# STM32H7B3x register map
File version: 2.2
CPU: CM7 r0p1, little endian, MPU, FPU, 4 interrupt priority bits
Registers are 32-bit, read-write, reset 0x0 unless marked. A register's access mark holds for its fields unless they carry their own. Offsets are from the block's base; [hi:lo] are bit positions; lines under a group give offsets from that group; {n}, {i} and the like mark numbered series.

## DFSDM1 — Digital filter for sigma delta modulators
Base 0x40017800
Same registers: DFSDM2 0x58006C00
{0x0+0x20*i} CH{i} (i=0..7) group — Cluster CH{i}, containing CH?CFGR1, CH?CFGR2, CH?AWSCDR, CH?WDATR, CH?DATINR, CH?DLYR
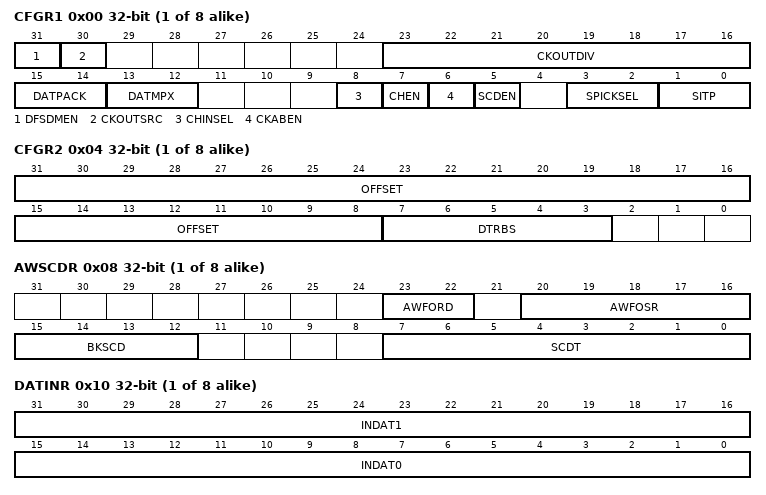
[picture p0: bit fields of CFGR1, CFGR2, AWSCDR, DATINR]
  0x00 CFGR1 — DFSDM channel 0 configuration register
    [31] DFSDMEN — Global enable for DFSDM interface If DFSDM interface is enabled, then it is started to operate according to enabled y channels and enabled x filters settings (CHEN bit in DFSDM_CHyCFGR1 and DFEN bit in DFSDM_FLTxCR1). Data cleared by setting DFSDMEN=0: all registers DFSDM_FLTxISR are set to reset state (x = 0..7) all registers DFSDM_FLTxAWSR are set to reset state (x = 0..7) Note: DFSDMEN is present only in DFSDM_CH0CFGR1 register (channel y=0)
    [30] CKOUTSRC — Output serial clock source selection This value can be modified only when DFSDMEN=0 (in DFSDM_CH0CFGR1 register). Note: CKOUTSRC is present only in DFSDM_CH0CFGR1 register (channel y=0)
    [23:16] CKOUTDIV — Output serial clock divider Â 256 (Divider = CKOUTDIV+1). CKOUTDIV also defines the threshold for a clock absence detection. This value can only be modified when DFSDMEN=0 (in DFSDM_CH0CFGR1 register). If DFSDMEN=0 (in DFSDM_CH0CFGR1 register) then CKOUT signal is set to low state (setting is performed one DFSDM clock cycle after DFSDMEN=0). Note: CKOUTDIV is present only in DFSDM_CH0CFGR1 register (channel y=0) 1- 255: Defines the division of system clock for the serial clock output for CKOUT signal in range 2Â -
    [15:14] DATPACK — Data packing mode in DFSDM_CHyDATINR register. first sample in INDAT0[15:0] (assigned to channel y) second sample INDAT1[15:0] (assigned to channel y) To empty DFSDM_CHyDATINR register, two samples must be read by the digital filter from channel y (INDAT0[15:0] part is read as first sample and then INDAT1[15:0] part is read as next sample). 2: Dual: input data in DFSDM_CHyDATINR register are stored as two samples: first sample INDAT0[15:0] (assigned to channel y) second sample INDAT1[15:0] (assigned to channel y+1) To empty DFSDM_CHyDATINR register first sample must be read by the digital filter from channel y and second sample must be read by another digital filter from channel y+1. Dual mode is available only on even channel numbers (y = 0, 2, 4, 6), for odd channel numbers (y = 1, 3, 5, 7) DFSDM_CHyDATINR is write protected. If an even channel is set to dual mode then the following odd channel must be set into standard mode (DATPACK[1:0]=0) for correct cooperation with even channel. 3: Reserved This value can be modified only when CHEN=0 (in DFSDM_CHyCFGR1 register).
    [13:12] DATMPX — Input data multiplexer for channel y 2: Data to channel y are taken from internal DFSDM_CHyDATINR register by direct CPU/DMA write. There can be written one or two 16-bit data samples according DATPACK[1:0] bit field setting. 3: Reserved This value can be modified only when CHEN=0 (in DFSDM_CHyCFGR1 register).
    [8] CHINSEL — Channel inputs selection This value can be modified only when CHEN=0 (in DFSDM_CHyCFGR1 register).
    [7] CHEN — Channel y enable If channel y is enabled, then serial data receiving is started according to the given channel setting.
    [6] CKABEN — Clock absence detector enable on channel y
    [5] SCDEN — Short-circuit detector enable on channel y
    [3:2] SPICKSEL — SPI clock select for channel y 2: clock coming from internal CKOUT - sampling point on each second CKOUT falling edge. For connection to external Î£â modulator which divides its clock input (from CKOUT) by 2 to generate its output serial communication clock (and this output clock change is active on each clock input rising edge). 3: clock coming from internal CKOUT output - sampling point on each second CKOUT rising edge. For connection to external Î£â modulator which divides its clock input (from CKOUT) by 2 to generate its output serial communication clock (and this output clock change is active on each clock input falling edge). This value can be modified only when CHEN=0 (in DFSDM_CHyCFGR1 register).
    [1:0] SITP — Serial interface type for channel y This value can only be modified when CHEN=0 (in DFSDM_CHyCFGR1 register).
  0x04 CFGR2 — DFSDM channel 0 configuration register
    [31:8] OFFSET — 24-bit calibration offset for channel y For channel y, OFFSET is applied to the results of each conversion from this channel. This value is set by software.
    [7:3] DTRBS — Data right bit-shift for channel y will be performed to have final results. Bit-shift is performed before offset correction. The data shift is rounding the result to nearest integer value. The sign of shifted result is maintained (to have valid 24-bit signed format of result data). This value can be modified only when CHEN=0 (in DFSDM_CHyCFGR1 register). 0-31: Defines the shift of the data result coming from the integrator - how many bit shifts to the right
  0x08 AWSCDR — DFSDM channel 0 analog watchdog and short-circuit detector register
    [23:22] AWFORD — Analog watchdog Sinc filter order on channel y 2: Sinc2 filter type 3: Sinc3 filter type Sincx filter type transfer function: FastSinc filter type transfer function: This bit can be modified only when CHEN=0 (in DFSDM_CHyCFGR1 register).
    [20:16] AWFOSR — Analog watchdog filter oversampling ratio (decimation rate) on channel y also the decimation ratio of the analog data rate. This bit can be modified only when CHEN=0 (in DFSDM_CHyCFGR1 register). Note: If AWFOSR = 0 then the filter has no effect (filter bypass). 0 - 31: Defines the length of the Sinc type filter in the range 1 - 32 (AWFOSR + 1). This number is
    [15:12] BKSCD — Break signal assignment for short-circuit detector on channel y BKSCD[i] = 0: Break i signal not assigned to short-circuit detector on channel y BKSCD[i] = 1: Break i signal assigned to short-circuit detector on channel y
    [7:0] SCDT — short-circuit detector threshold for channel y These bits are written by software to define the threshold counter for the short-circuit detector. If this value is reached, then a short-circuit detector event occurs on a given channel.
  0x0C WDATR ro — DFSDM channel 0 watchdog filter data register
    [15:0] WDATA — Input channel y watchdog data Data converted by the analog watchdog filter for input channel y. This data is continuously converted (no trigger) for this channel, with a limited resolution (OSR=1..32/sinc order = 1..3).
  0x10 DATINR — DFSDM channel 0 data input register
    [31:16] INDAT1 — Input data for channel y or channel y+1 Input parallel channel data to be processed by the digital filter if DATMPX[1:0]=1 or DATMPX[1:0]=2. Data can be written by CPU/DMA (if DATMPX[1:0]=2) or directly by internal ADC (if DATMPX[1:0]=1). If DATPACK[1:0]=0 (standard mode) INDAT0[15:0] is write protected (not used for input sample). If DATPACK[1:0]=1 (interleaved mode) Second channel y data sample is stored into INDAT1[15:0]. First channel y data sample is stored into INDAT0[15:0]. Both samples are read sequentially by DFSDM_FLTx filter as two channel y data samples. If DATPACK[1:0]=2 (dual mode). For even y channels: sample in INDAT1[15:0] is automatically copied into INDAT0[15:0] of channel (y+1). For odd y channels: INDAT1[15:0] is write protected. See for more details. INDAT0[15:1] is in the16-bit signed format.
    [15:0] INDAT0 — Input data for channel y Input parallel channel data to be processed by the digital filter if DATMPX[1:0]=1 or DATMPX[1:0]=2. Data can be written by CPU/DMA (if DATMPX[1:0]=2) or directly by internal ADC (if DATMPX[1:0]=1). If DATPACK[1:0]=0 (standard mode) Channel y data sample is stored into INDAT0[15:0]. If DATPACK[1:0]=1 (interleaved mode) First channel y data sample is stored into INDAT0[15:0]. Second channel y data sample is stored into INDAT1[15:0]. Both samples are read sequentially by DFSDM_FLTx filter as two channel y data samples. If DATPACK[1:0]=2 (dual mode). For even y channels: Channel y data sample is stored into INDAT0[15:0]. For odd y channels: INDAT0[15:0] is write protected. See for more details. INDAT0[15:0] is in the16-bit signed format.
  0x14 DLYR
    [5:0] PLSSKP — Pulses to skip for input data skipping function immediately after writing to this field. Reading of PLSSKP[5:0] returns current value of pulses which will be skipped. If PLSSKP[5:0]=0 then all required data samples were already skipped. Note: User can update PLSSKP[5:0] also when PLSSKP[5:0] is not zero. 0-63: Defines the number of serial input samples that will be skipped. Skipping is applied
{0x100+0x80*i} FLT{i} (i=0..7) group — Cluster FLT{i}, containing FLT?CR1, FLT?CR2, FLT?ISR, FLT?ICR, FLT?JCHGR, FLT?FCR, FLT?JDATAR, FLT?RDATAR, FLT?AWHTR, FLT?AWLTR, FLT?AWSR, FLT?AWCFR, FLT?EXMAX, FLT?EXMIN, FLT?CNVTIMR
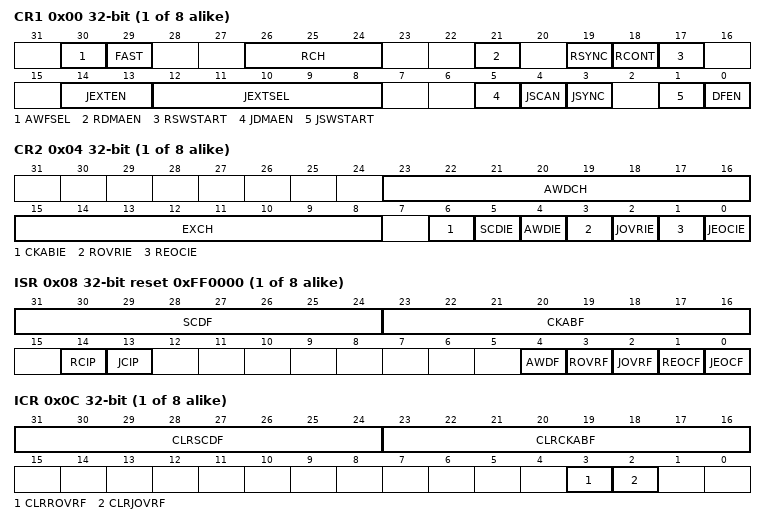
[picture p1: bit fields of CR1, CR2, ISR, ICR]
  0x00 CR1
    [30] AWFSEL — Analog watchdog fast mode select
    [29] FAST — Fast conversion mode selection for regular conversions When converting a regular conversion in continuous mode, having enabled the fast mode causes each conversion (except the first) to execute faster than in standard mode. This bit has no effect on conversions which are not continuous. This bit can be modified only when DFEN=0 (DFSDM_FLTxCR1). if FAST=0 (or first conversion in continuous mode if FAST=1): t = [FOSR * (IOSR-1 + FORD) + FORD] / fCKIN ..... for Sincx filters t = [FOSR * (IOSR-1 + 4) + 2] / fCKIN ..... for FastSinc filter if FAST=1 in continuous mode (except first conversion): t = [FOSR * IOSR] / fCKIN in case if FOSR = FOSR[9:0]+1 = 1 (filter bypassed, active only integrator): t = IOSR / fCKIN (... but CNVCNT=0) where: fCKIN is the channel input clock frequency (on given channel CKINy pin) or input data rate in case of parallel data input.
    [26:24] RCH — Regular channel selection ... 7: Channel 7 is selected as the regular channel Writing these bits when RCIP=1 takes effect when the next regular conversion begins. This is especially useful in continuous mode (when RCONT=1). It also affects regular conversions which are pending (due to ongoing injected conversion).
    [21] RDMAEN — DMA channel enabled to read data for the regular conversion This bit can be modified only when DFEN=0 (DFSDM_FLTxCR1).
    [19] RSYNC — Launch regular conversion synchronously with DFSDM_FLT0 This bit can be modified only when DFEN=0 (DFSDM_FLTxCR1).
    [18] RCONT — Continuous mode selection for regular conversions Writing '0â to this bit while a continuous regular conversion is already in progress stops the continuous mode immediately.
    [17] RSWSTART — Software start of a conversion on the regular channel This bit is always read as '0â.
    [14:13] JEXTEN — Trigger enable and trigger edge selection for injected conversions This bit can be modified only when DFEN=0 (DFSDM_FLTxCR1).
    [12:8] JEXTSEL — Trigger signal selection for launching injected conversions This bit can be modified only when DFEN=0 (DFSDM_FLTxCR1). Note: synchronous trigger has latency up to one fDFSDMCLK clock cycle (with deterministic jitter), asynchronous trigger has latency 2-3 fDFSDMCLK clock cycles (with jitter up to 1 cycle). DFSDM_FLTx 0x00 dfsdm_jtrg0 0x01 dfsdm_jtrg1 ... 0x1E dfsdm_jtrg30 0x1F dfsdm_jtrg31 Refer to . 0x0-0x1F: Trigger inputs selected by the following table (internal or external trigger).
    [5] JDMAEN — DMA channel enabled to read data for the injected channel group This bit can be modified only when DFEN=0 (DFSDM_FLTxCR1).
    [4] JSCAN — Scanning conversion mode for injected conversions This bit can be modified only when DFEN=0 (DFSDM_FLTxCR1). Writing JCHG if JSCAN=0 resets the channel selection to the lowest selected channel.
    [3] JSYNC — Launch an injected conversion synchronously with the DFSDM_FLT0 JSWSTART trigger This bit can be modified only when DFEN=0 (DFSDM_FLTxCR1).
    [1] JSWSTART — Start a conversion of the injected group of channels This bit is always read as '0â.
    [0] DFEN — DFSDM_FLTx enable Data which are cleared by setting DFEN=0: register DFSDM_FLTxISR is set to the reset state register DFSDM_FLTxAWSR is set to the reset state
  0x04 CR2
    [23:16] AWDCH — Analog watchdog channel selection These bits select the input channel to be guarded continuously by the analog watchdog. AWDCH[y] = 0: Analog watchdog is disabled on channel y AWDCH[y] = 1: Analog watchdog is enabled on channel y
    [15:8] EXCH — Extremes detector channel selection These bits select the input channels to be taken by the Extremes detector. EXCH[y] = 0: Extremes detector does not accept data from channel y EXCH[y] = 1: Extremes detector accepts data from channel y
    [6] CKABIE — Clock absence interrupt enable Please see the explanation of CKABF[7:0] in DFSDM_FLTxISR. Note: CKABIE is present only in DFSDM_FLT0CR2 register (filter x=0)
    [5] SCDIE — Short-circuit detector interrupt enable Please see the explanation of SCDF[7:0] in DFSDM_FLTxISR. Note: SCDIE is present only in DFSDM_FLT0CR2 register (filter x=0)
    [4] AWDIE — Analog watchdog interrupt enable Please see the explanation of AWDF in DFSDM_FLTxISR.
    [3] ROVRIE — Regular data overrun interrupt enable Please see the explanation of ROVRF in DFSDM_FLTxISR.
    [2] JOVRIE — Injected data overrun interrupt enable Please see the explanation of JOVRF in DFSDM_FLTxISR.
    [1] REOCIE — Regular end of conversion interrupt enable Please see the explanation of REOCF in DFSDM_FLTxISR.
    [0] JEOCIE — Injected end of conversion interrupt enable Please see the explanation of JEOCF in DFSDM_FLTxISR.
  0x08 ISR ro reset 0xFF0000
    [31:24] SCDF — short-circuit detector flag SDCF[y]=0: No short-circuit detector event occurred on channel y SDCF[y]=1: The short-circuit detector counter reaches, on channel y, the value programmed in the DFSDM_CHyAWSCDR registers This bit is set by hardware. It can be cleared by software using the corresponding CLRSCDF[y] bit in the DFSDM_FLTxICR register. SCDF[y] is cleared also by hardware when CHEN[y] = 0 (given channel is disabled). Note: SCDF[7:0] is present only in DFSDM_FLT0ISR register (filter x=0)
    [23:16] CKABF — Clock absence flag CKABF[y]=0: Clock signal on channel y is present. CKABF[y]=1: Clock signal on channel y is not present. Given y bit is set by hardware when clock absence is detected on channel y. It is held at CKABF[y]=1 state by hardware when CHEN=0 (see DFSDM_CHyCFGR1 register). It is held at CKABF[y]=1 state by hardware when the transceiver is not yet synchronized.It can be cleared by software using the corresponding CLRCKABF[y] bit in the DFSDM_FLTxICR register. Note: CKABF[7:0] is present only in DFSDM_FLT0ISR register (filter x=0)
    [14] RCIP — Regular conversion in progress status A request to start a regular conversion is ignored when RCIP=1.
    [13] JCIP — Injected conversion in progress status A request to start an injected conversion is ignored when JCIP=1.
    [4] AWDF — Analog watchdog This bit is set by hardware. It is cleared by software by clearing all source flag bits AWHTF[7:0] and AWLTF[7:0] in DFSDM_FLTxAWSR register (by writing '1â into the clear bits in DFSDM_FLTxAWCFR register).
    [3] ROVRF — Regular conversion overrun flag This bit is set by hardware. It can be cleared by software using the CLRROVRF bit in the DFSDM_FLTxICR register.
    [2] JOVRF — Injected conversion overrun flag This bit is set by hardware. It can be cleared by software using the CLRJOVRF bit in the DFSDM_FLTxICR register.
    [1] REOCF — End of regular conversion flag This bit is set by hardware. It is cleared when the software or DMA reads DFSDM_FLTxRDATAR.
    [0] JEOCF — End of injected conversion flag This bit is set by hardware. It is cleared when the software or DMA reads DFSDM_FLTxJDATAR.
  0x0C ICR
    [31:24] CLRSCDF — Clear the short-circuit detector flag CLRSCDF[y]=0: Writing '0â has no effect CLRSCDF[y]=1: Writing '1â to position y clears the corresponding SCDF[y] bit in the DFSDM_FLTxISR register Note: CLRSCDF[7:0] is present only in DFSDM_FLT0ICR register (filter x=0)
    [23:16] CLRCKABF — Clear the clock absence flag CLRCKABF[y]=0: Writing '0â has no effect CLRCKABF[y]=1: Writing '1â to position y clears the corresponding CKABF[y] bit in the DFSDM_FLTxISR register. When the transceiver is not yet synchronized, the clock absence flag is set and cannot be cleared by CLRCKABF[y]. Note: CLRCKABF[7:0] is present only in DFSDM_FLT0ICR register (filter x=0)
    [3] CLRROVRF — Clear the regular conversion overrun flag
    [2] CLRJOVRF — Clear the injected conversion overrun flag
  0x10 JCHGR reset 0x1
    [7:0] JCHG — Injected channel group selection JCHG[y]=0: channel y is not part of the injected group JCHG[y]=1: channel y is part of the injected group If JSCAN=1, each of the selected channels is converted, one after another. The lowest channel (channel 0, if selected) is converted first and the sequence ends at the highest selected channel. If JSCAN=0, then only one channel is converted from the selected channels, and the channel selection is moved to the next channel. Writing JCHG, if JSCAN=0, resets the channel selection to the lowest selected channel. At least one channel must always be selected for the injected group. Writes causing all JCHG bits to be zero are ignored.
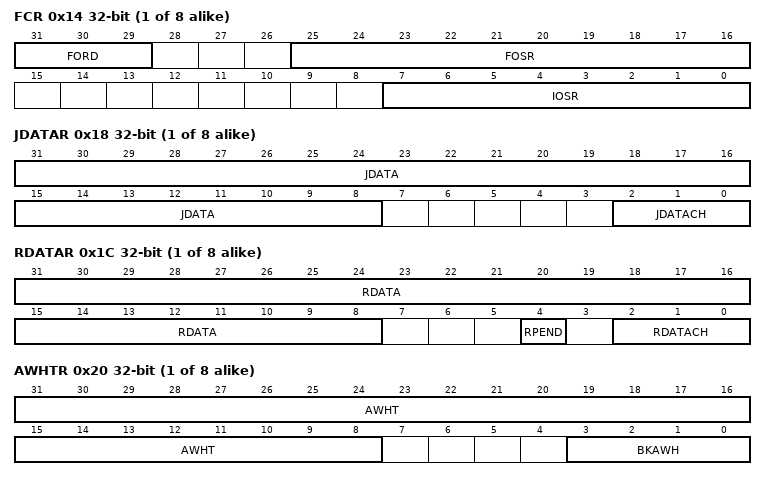
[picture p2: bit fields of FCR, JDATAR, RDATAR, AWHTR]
  0x14 FCR
    [31:29] FORD — Sinc filter order 2: Sinc2 filter type 3: Sinc3 filter type 4: Sinc4 filter type 5: Sinc5 filter type 6-7: Reserved Sincx filter type transfer function: FastSinc filter type transfer function: This bit can only be modified when DFEN=0 (DFSDM_FLTxCR1).
    [25:16] FOSR — Sinc filter oversampling ratio (decimation rate) number is also the decimation ratio of the output data rate from filter. This bit can only be modified when DFEN=0 (DFSDM_FLTxCR1) Note: If FOSR = 0, then the filter has no effect (filter bypass). 0 - 1023: Defines the length of the Sinc type filter in the range 1 - 1024 (FOSR = FOSR[9:0] +1). This
    [7:0] IOSR — Integrator oversampling ratio (averaging length) from Sinc filter will be summed into one output data sample from the integrator. The output data rate from the integrator will be decreased by this number (additional data decimation ratio). This bit can only be modified when DFEN=0 (DFSDM_FLTxCR1) Note: If IOSR = 0, then the Integrator has no effect (Integrator bypass). 0- 255: The length of the Integrator in the range 1 - 256 (IOSR + 1). Defines how many samples
  0x18 JDATAR ro
    [31:8] JDATA — Injected group conversion data When each conversion of a channel in the injected group finishes, its resulting data is stored in this field. The data is valid when JEOCF=1. Reading this register clears the corresponding JEOCF.
    [2:0] JDATACH — Injected channel most recently converted When each conversion of a channel in the injected group finishes, JDATACH[2:0] is updated to indicate which channel was converted. Thus, JDATA[23:0] holds the data that corresponds to the channel indicated by JDATACH[2:0].
  0x1C RDATAR ro
    [31:8] RDATA — Regular channel conversion data When each regular conversion finishes, its data is stored in this register. The data is valid when REOCF=1. Reading this register clears the corresponding REOCF.
    [4] RPEND — Regular channel pending data Regular data in RDATA[23:0] was delayed due to an injected channel trigger during the conversion
    [2:0] RDATACH — Regular channel most recently converted When each regular conversion finishes, RDATACH[2:0] is updated to indicate which channel was converted (because regular channel selection RCH[2:0] in DFSDM_FLTxCR1 register can be updated during regular conversion). Thus RDATA[23:0] holds the data that corresponds to the channel indicated by RDATACH[2:0].
  0x20 AWHTR
    [31:8] AWHT — Analog watchdog high threshold These bits are written by software to define the high threshold for the analog watchdog. Note: In case channel transceivers monitor (AWFSEL=1), the higher 16 bits (AWHT[23:8]) define the 16-bit threshold as compared with the analog watchdog filter output (because data coming from the analog watchdog filter are up to a 16-bit resolution). Bits AWHT[7:0] are not taken into comparison in this case.
    [3:0] BKAWH — Break signal assignment to analog watchdog high threshold event BKAWH[i] = 0: Break i signal is not assigned to an analog watchdog high threshold event BKAWH[i] = 1: Break i signal is assigned to an analog watchdog high threshold event
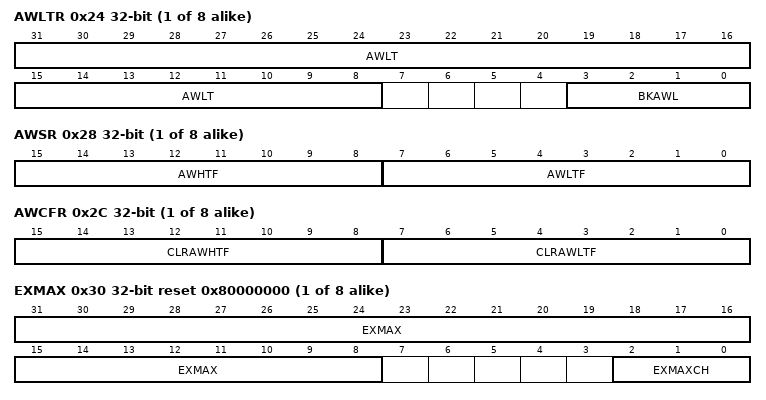
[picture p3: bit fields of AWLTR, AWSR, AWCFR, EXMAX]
  0x24 AWLTR
    [31:8] AWLT — Analog watchdog low threshold These bits are written by software to define the low threshold for the analog watchdog. Note: In case channel transceivers monitor (AWFSEL=1), only the higher 16 bits (AWLT[23:8]) define the 16-bit threshold as compared with the analog watchdog filter output (because data coming from the analog watchdog filter are up to a 16-bit resolution). Bits AWLT[7:0] are not taken into comparison in this case.
    [3:0] BKAWL — Break signal assignment to analog watchdog low threshold event BKAWL[i] = 0: Break i signal is not assigned to an analog watchdog low threshold event BKAWL[i] = 1: Break i signal is assigned to an analog watchdog low threshold event
  0x28 AWSR ro
    [15:8] AWHTF — Analog watchdog high threshold flag AWHTF[y]=1 indicates a high threshold error on channel y. It is set by hardware. It can be cleared by software using the corresponding CLRAWHTF[y] bit in the DFSDM_FLTxAWCFR register.
    [7:0] AWLTF — Analog watchdog low threshold flag AWLTF[y]=1 indicates a low threshold error on channel y. It is set by hardware. It can be cleared by software using the corresponding CLRAWLTF[y] bit in the DFSDM_FLTxAWCFR register.
  0x2C AWCFR
    [15:8] CLRAWHTF — Clear the analog watchdog high threshold flag CLRAWHTF[y]=0: Writing '0â has no effect CLRAWHTF[y]=1: Writing '1â to position y clears the corresponding AWHTF[y] bit in the DFSDM_FLTxAWSR register
    [7:0] CLRAWLTF — Clear the analog watchdog low threshold flag CLRAWLTF[y]=0: Writing '0â has no effect CLRAWLTF[y]=1: Writing '1â to position y clears the corresponding AWLTF[y] bit in the DFSDM_FLTxAWSR register
  0x30 EXMAX ro reset 0x80000000
    [31:8] EXMAX read-sets — Extremes detector maximum value These bits are set by hardware and indicate the highest value converted by DFSDM_FLTx. EXMAX[23:0] bits are reset to value (0x800000) by reading of this register.
    [2:0] EXMAXCH — Extremes detector maximum data channel. These bits contains information about the channel on which the data is stored into EXMAX[23:0]. Bits are cleared by reading of this register.
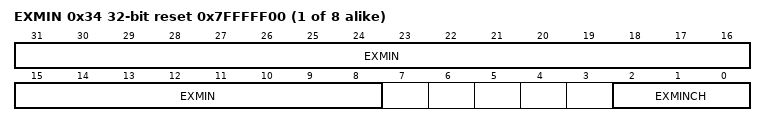
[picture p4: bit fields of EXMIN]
  0x34 EXMIN access per field reset 0x7FFFFF00
    [31:8] EXMIN rw read-clears — Extremes detector minimum value These bits are set by hardware and indicate the lowest value converted by DFSDM_FLTx. EXMIN[23:0] bits are reset to value (0x7FFFFF) by reading of this register.
    [2:0] EXMINCH ro — Extremes detector minimum data channel These bits contain information about the channel on which the data is stored into EXMIN[23:0]. Bits are cleared by reading of this register.
  0x38 FLTCNVTIMR ro
    [31:4] CNVCNT — 28-bit timer counting conversion time t = CNVCNT[27:0] / fDFSDMCLK The timer has an input clock from DFSDM clock (system clock fDFSDMCLK). Conversion time measurement is started on each conversion start and stopped when conversion finishes (interval between first and last serial sample). Only in case of filter bypass (FOSR[9:0] = 0) is the conversion time measurement stopped and CNVCNT[27:0] = 0. The counted time is: if FAST=0 (or first conversion in continuous mode if FAST=1): t = [FOSR * (IOSR-1 + FORD) + FORD] / fCKIN ..... for Sincx filters t = [FOSR * (IOSR-1 + 4) + 2] / fCKIN ..... for FastSinc filter if FAST=1 in continuous mode (except first conversion): t = [FOSR * IOSR] / fCKIN in case if FOSR = FOSR[9:0]+1 = 1 (filter bypassed, active only integrator): CNVCNT = 0 (counting is stopped, conversion time: t = IOSR / fCKIN) where: fCKIN is the channel input clock frequency (on given channel CKINy pin) or input data rate in case of parallel data input (from internal ADC or from CPU/DMA write) Note: When conversion is interrupted (e.g. by disable/enable selected channel) the timer counts also this interruption time.
